# RK3399-AP register map
File version: 1
CPU: CA7 r0p1, little endian, MPU, FPU, I-cache, D-cache, VTOR, 4 interrupt priority bits, 0 interrupts
Registers are 32-bit, read-write, reset 0x0 unless marked. A register's access mark holds for its fields unless they carry their own. Offsets are from the block's base; [hi:lo] are bit positions; {n}, {i} and the like mark numbered series.

## SARADC
Base 0xFF100000
0x00 SARADC_DATA ro — This register contains the data after A/D Conversion.
  [9:0] ADC_DATA — A/D value of the last conversion (DOUT[9:0]).
0x04 SARADC_STAS ro — The status register of A/D Converter.
  [0] ADC_STATUS — ADC status (EOC) 0: ADC stop 1: Conversion in progress
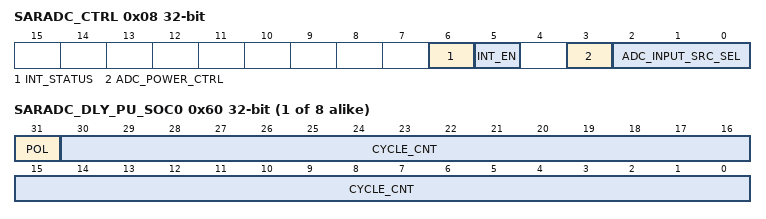
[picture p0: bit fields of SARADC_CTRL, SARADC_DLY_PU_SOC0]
0x08 SARADC_CTRL — The control register of A/D Converter.
  [6] INT_STATUS — Interrupt status. This bit will be set to 1 when end-of-conversion. Set 0 to clear the interrupt.
  [5] INT_EN — Interrupt enable. 0: Disable 1: Enable
  [3] ADC_POWER_CTRL — ADC power down control bit 0: ADC power down; 1: ADC power up and reset. start signal will be asserted (DLY_PU_SOC + 2) sclk clock period later after power up
  [2:0] ADC_INPUT_SRC_SEL — ADC input source selection(CH_SEL[2:0]). 000 : Input source 0 (SARADC_AIN[0]) 001 : Input source 1 (SARADC_AIN[1]) 010 : Input source 2 (SARADC_AIN[2]) 011 : Input source 3 (SARADC_AIN[3]) 100 : Input source 4 (SARADC_AIN[4]) 101 : Input source 5 (SARADC_AIN[5]) Others : Reserved
0x0C SARADC_DLY_PU_SOC — delay between power up and start command
  [5:0] DLY_PU_SOC — delay between power up and start command The start signal will be asserted (DLY_PU_SOC + 2) sclk clock period later after power up
{0x60+4i} SARADC_DLY_PU_SOC{i} access per field (i=0..7) — FIFO Register
  [31] POL rw — Polarity This bit indicates the polarity of the lower 31-bit counter. 0: Low 1: High
  [30:0] CYCLE_CNT ro — High/Low Cycle Counter This 31-bit counter indicates the effective cycles of high/low waveform.

## TIMER0
Base 0xFF850000
Same registers: PMUTIMER0 0xFF360000, PMUTIMER1 0xFF360020, TIMER1 0xFF850020, TIMER2 0xFF850040, TIMER3 0xFF850060, TIMER4 0xFF850080, TIMER5 0xFF850100, TIMER6 0xFF858000, TIMER7 0xFF858020, TIMER8 0xFF858040, TIMER9 0xFF858060, TIMER10 0xFF858080, TIMER11 0xFF858100, STIMER0 0xFF860000, STIMER1 0xFF860020, STIMER2 0xFF860040, STIMER3 0xFF860060, STIMER4 0xFF860080, STIMER5 0xFF860100, STIMER6 0xFF868000, STIMER7 0xFF868020, STIMER8 0xFF868040, STIMER9 0xFF868060, STIMER10 0xFF868080, STIMER11 0xFF868100
0x00 TIMER_n_LOAD_COUNT0 access not given — Timer n higher Load Count Register
0x04 TIMER_n_LOAD_COUNT1 access not given — Timer n higher Load Count Register
0x08 TIMER_n_CURRENT_VALUE0 access not given — Timer n Current Value Register
0x0C TIMER_n_CURRENT_VALUE1 access not given — Timer n Current Value Register
0x10 TIMER_n_LOAD_COUNT2 access not given — Timer n lower Load Count Register
0x14 TIMER_n_LOAD_COUNT3 access not given — Timer n lower Load Count Register
0x18 TIMER_n_INTSTATUS access not given — Timer Interrupt Stauts Register
0x1C TIMER_n_CONTROLREG access not given — Timer n Control Register

## MSCH0
Base 0xFFA84000
Same registers: MSCH1 0xFFA8C000
0x00 MSCH_Id_CoreId access not given reset 0xD867004 — Core ID register
0x04 MSCH_Id_RevisionId access not given reset 0x1AA00 — Revision ID register
0x08 MSCH_DeviceConf access not given — ddr configuration pointers
0x0C MSCH_DeviceSize access not given — ddr configuration sizes.
0x10 MSCH_DdrTimingA0 access not given reset 0x28140916 — DdrTimingA bank 0
0x14 MSCH_DdrTimingB0 access not given reset 0x40702 — DdrTimingB bank 0
0x18 MSCH_DdrTimingC0 access not given reset 0x2 — DdrTimingC bank 0
0x1C MSCH_DevToDev0 access not given reset 0x222 — Timing values concerning device to device data bus ownership c
0x110 MSCH_DdrMode access not given reset 0x4C — ddr mode definition.
0x1000 MSCH_AgingX0 access not given — Aging threshold multiplicator.

## CCI_PROBE_MSCH0
Base 0xFFA86000
Same registers: GPU_PROBE_MSCH0E 0xFFA86400, PERIHP_PROBE_MSCH0 0xFFA86800, PERILP_PROBE_MSCH0 0xFFA86C00, VIDEO_PROBE_MSCH0 0xFFA87000, VIO0_PROBE_MSCH0 0xFFA87400, VIO1_PROBE_MSCH0 0xFFA87800, CCI_PROBE_MSCH1 0xFFA8E000, GPU_PROBE_MSCH1 0xFFA8E400, PERIHP_PROBE_MSCH1 0xFFA8E800, PERILP_PROBE_MSCH1 0xFFA8EC00, VIDEO_PROBE_MSCH1 0xFFA8F000, VIO0_PROBE_MSCH1 0xFFA8F400, VIO1_PROBE_MSCH1 0xFFA8F800
0x00 PROBE_Id_CoreId access not given reset 0xD867006 — Core ID register
0x04 PROBE_Id_RevisionId access not given reset 0x1AA00 — Revision ID register
0x08 PROBE_MainCtl access not given — Register MainCtl contains probe global control bits.
0x0C PROBE_CfgCtl access not given — Register CfgCtl contains global enable and active bits.
0x24 PROBE_StatPeriod access not given — Statistics Period
0x28 PROBE_StatGo access not given — Statistics start to dump
{0x138+0x14*i} PROBE_Counters_{i}_Src access not given (i=0..3) — Register CntSrc indicates the event source.
{0x13C+0x14*i} PROBE_Counters_{i}_Val access not given (i=0..3) — Registers Counters_M_Val contain the statistics counter values.
